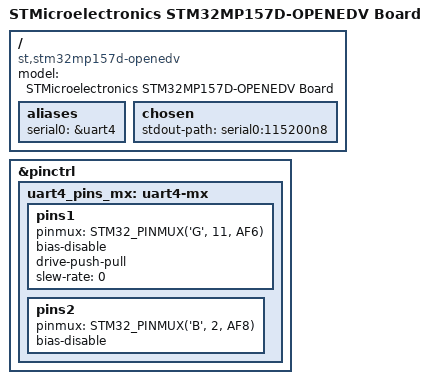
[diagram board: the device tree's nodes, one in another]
// SPDX-License-Identifier: (GPL-2.0+ OR BSD-3-Clause)
/*
 * Copyright (C) STMicroelectronics 2019 - All Rights Reserved
 * Author: Alexandre Torgue <alexandre.torgue@st.com> for STMicroelectronics.
 */
/dts-v1/;

#include "stm32mp157.dtsi"
#include "stm32mp15xd.dtsi"
#include "stm32mp15-pinctrl.dtsi"
#include "stm32mp15xxaa-pinctrl.dtsi"
#include "stm32mp157d-openedv.dtsi"

/ {
	model = "STMicroelectronics STM32MP157D-OPENEDV Board";
	compatible = "st,stm32mp157d-openedv", "st,stm32mp157";

	aliases {
		serial0 = &uart4;
	};

	chosen {
		stdout-path = "serial0:115200n8";
	};
};

&pinctrl {
	uart4_pins_mx: uart4-mx {
		pins1 {
			pinmux = <STM32_PINMUX('G', 11, AF6)>; /* UART4_TX */
			bias-disable;
			drive-push-pull;
			slew-rate = <0>;
		};
		pins2 {
			pinmux = <STM32_PINMUX('B', 2, AF8)>; /* UART4_RX */
			bias-disable;
		};
	};
};
